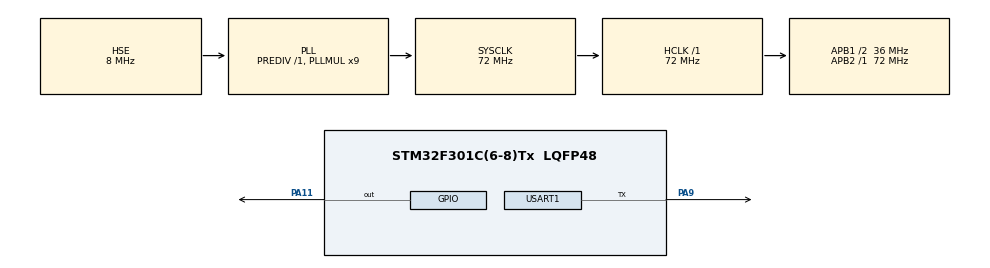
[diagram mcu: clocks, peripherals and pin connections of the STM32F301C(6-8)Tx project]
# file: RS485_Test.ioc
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Mcu.Family=STM32F3
Mcu.Name=STM32F301C(6-8)Tx
Mcu.Package=LQFP48
NVIC.PriorityGroup=NVIC_PRIORITYGROUP_4
PA10.Signal=USART1_RX
PA11.GPIO_Speed=GPIO_SPEED_FREQ_MEDIUM
PA11.Signal=GPIO_Output
PA9.Mode=ModbusCommunication
PA9.Signal=USART1_TX
PF0-OSC_IN.Mode=HSE-External-Oscillator
PF0-OSC_IN.Signal=RCC_OSC_IN
PF1-OSC_OUT.Mode=HSE-External-Oscillator
PF1-OSC_OUT.Signal=RCC_OSC_OUT
ProjectManager.HeapSize=0x200
ProjectManager.StackSize=0x400
ProjectManager.TargetToolchain=STM32CubeIDE
RCC.AHBFreq_Value=72000000
RCC.APB1CLKDivider=RCC_HCLK_DIV2
RCC.APB1Freq_Value=36000000
RCC.APB1TimFreq_Value=72000000
RCC.APB2Freq_Value=72000000
RCC.APB2TimFreq_Value=72000000
RCC.CortexFreq_Value=72000000
RCC.HCLKFreq_Value=72000000
RCC.HSE_VALUE=8000000
RCC.HSI_VALUE=8000000
RCC.LSE_VALUE=32768
RCC.PLLMUL=RCC_PLL_MUL9
RCC.PLLSourceVirtual=RCC_PLLSOURCE_HSE
RCC.SYSCLKFreq_VALUE=72000000
RCC.SYSCLKSourceVirtual=RCC_SYSCLKSOURCE_PLLCLK
board=custom

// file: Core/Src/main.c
/* USER CODE BEGIN Header */
/**
  ******************************************************************************
  * @file           : main.c
  * @brief          : Main program body
  ******************************************************************************
  * @attention
  *
  * <h2><center>&copy; Copyright (c) 2020 STMicroelectronics.
  * All rights reserved.</center></h2>
  *
  * This software component is licensed by ST under BSD 3-Clause license,
  * the "License"; You may not use this file except in compliance with the
  * License. You may obtain a copy of the License at:
  *                        opensource.org/licenses/BSD-3-Clause
  *
  ******************************************************************************
  */
/* USER CODE END Header */
#include "main.h"

void SystemClock_Config(void);
static void MX_GPIO_Init(void);
static void MX_USART1_Init(void);

int main(void)
{

  /* MCU Configuration--------------------------------------------------------*/

  /* Reset of all peripherals, Initializes the Flash interface and the Systick. */
  HAL_Init();

  /* Configure the system clock */
  SystemClock_Config();

  /* Initialize all configured peripherals */
  MX_GPIO_Init();
  MX_USART1_Init();
  /* USER CODE BEGIN 2 */
  HAL_GPIO_WritePin(GPIOA, GPIO_PIN_11, GPIO_PIN_SET);
  HAL_GPIO_WritePin(GPIOA, GPIO_PIN_11, GPIO_PIN_RESET);
  /* USER CODE END 2 */

  /* Infinite loop */
  while (1)
  {

  }
}

void SystemClock_Config(void)
{
  RCC_OscInitTypeDef RCC_OscInitStruct = {0};
  RCC_ClkInitTypeDef RCC_ClkInitStruct = {0};
  RCC_PeriphCLKInitTypeDef PeriphClkInit = {0};

  /** Initializes the RCC Oscillators according to the specified parameters
  * in the RCC_OscInitTypeDef structure.
  */
  RCC_OscInitStruct.OscillatorType = RCC_OSCILLATORTYPE_HSE;
  RCC_OscInitStruct.HSEState = RCC_HSE_ON;
  RCC_OscInitStruct.HSEPredivValue = RCC_HSE_PREDIV_DIV1;
  RCC_OscInitStruct.HSIState = RCC_HSI_ON;
  RCC_OscInitStruct.PLL.PLLState = RCC_PLL_ON;
  RCC_OscInitStruct.PLL.PLLSource = RCC_PLLSOURCE_HSE;
  RCC_OscInitStruct.PLL.PLLMUL = RCC_PLL_MUL9;
  if (HAL_RCC_OscConfig(&RCC_OscInitStruct) != HAL_OK)
  {
    Error_Handler();
  }
  /** Initializes the CPU, AHB and APB buses clocks
  */
  RCC_ClkInitStruct.ClockType = RCC_CLOCKTYPE_HCLK|RCC_CLOCKTYPE_SYSCLK
                              |RCC_CLOCKTYPE_PCLK1|RCC_CLOCKTYPE_PCLK2;
  RCC_ClkInitStruct.SYSCLKSource = RCC_SYSCLKSOURCE_PLLCLK;
  RCC_ClkInitStruct.AHBCLKDivider = RCC_SYSCLK_DIV1;
  RCC_ClkInitStruct.APB1CLKDivider = RCC_HCLK_DIV2;
  RCC_ClkInitStruct.APB2CLKDivider = RCC_HCLK_DIV1;

  if (HAL_RCC_ClockConfig(&RCC_ClkInitStruct, FLASH_LATENCY_2) != HAL_OK)
  {
    Error_Handler();
  }
  PeriphClkInit.PeriphClockSelection = RCC_PERIPHCLK_USART1;
  PeriphClkInit.Usart1ClockSelection = RCC_USART1CLKSOURCE_PCLK1;
  if (HAL_RCCEx_PeriphCLKConfig(&PeriphClkInit) != HAL_OK)
  {
    Error_Handler();
  }
}

static void MX_USART1_Init(void)
{

}

static void MX_GPIO_Init(void)
{
  GPIO_InitTypeDef GPIO_InitStruct = {0};

  /* GPIO Ports Clock Enable */
  __HAL_RCC_GPIOF_CLK_ENABLE();
  __HAL_RCC_GPIOA_CLK_ENABLE();

  /*Configure GPIO pin Output Level */
  HAL_GPIO_WritePin(GPIOA, GPIO_PIN_11, GPIO_PIN_RESET);

  /*Configure GPIO pins : PA9 PA10 */
  GPIO_InitStruct.Pin = GPIO_PIN_9|GPIO_PIN_10;
  GPIO_InitStruct.Mode = GPIO_MODE_AF_PP;
  GPIO_InitStruct.Pull = GPIO_NOPULL;
  GPIO_InitStruct.Speed = GPIO_SPEED_FREQ_HIGH;
  GPIO_InitStruct.Alternate = GPIO_AF7_USART1;
  HAL_GPIO_Init(GPIOA, &GPIO_InitStruct);

  /*Configure GPIO pin : PA11 */
  GPIO_InitStruct.Pin = GPIO_PIN_11;
  GPIO_InitStruct.Mode = GPIO_MODE_OUTPUT_PP;
  GPIO_InitStruct.Pull = GPIO_NOPULL;
  GPIO_InitStruct.Speed = GPIO_SPEED_FREQ_MEDIUM;
  HAL_GPIO_Init(GPIOA, &GPIO_InitStruct);

}

void Error_Handler(void)
{
}

/************************ (C) COPYRIGHT STMicroelectronics *****END OF FILE****/
